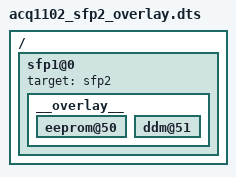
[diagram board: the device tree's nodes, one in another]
/dts-v1/;
/plugin/;	/* allow undefined label references and record them */
/ {
	sfp1@0 {
		target = <&sfp2>;
		__overlay__ {
			eeprom@50 {
				status="okay";
			};
			ddm@51 {
				status="okay";
			};
		};
	};
};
